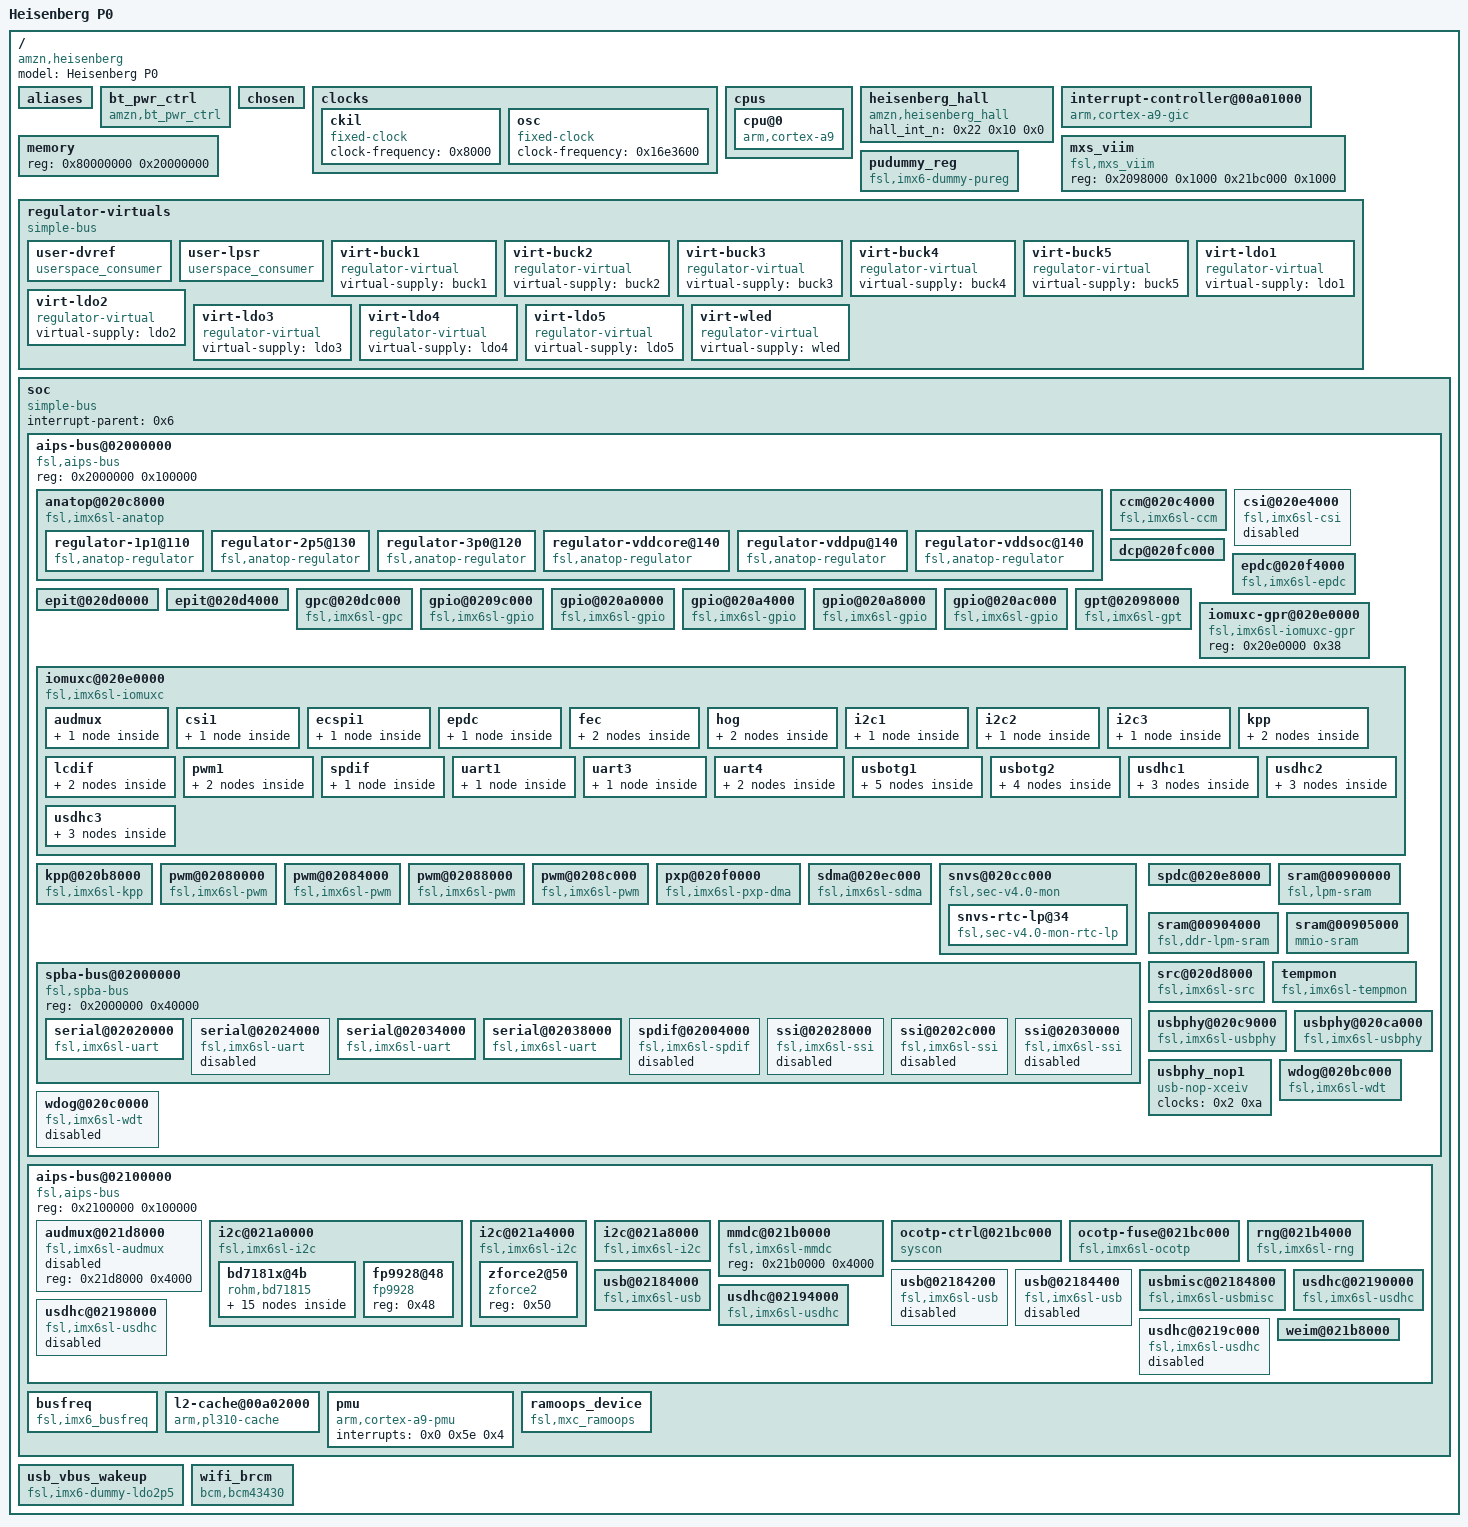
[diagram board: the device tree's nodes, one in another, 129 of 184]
/dts-v1/;

/ {
	#address-cells = <0x1>;
	#size-cells = <0x1>;
	compatible = "amzn,heisenberg", "fsl,imx6sl";
	model = "Heisenberg P0";

	aliases {
		csi0 = "/soc/aips-bus@02000000/csi@020e4000";
		gpio0 = "/soc/aips-bus@02000000/gpio@0209c000";
		gpio1 = "/soc/aips-bus@02000000/gpio@020a0000";
		gpio2 = "/soc/aips-bus@02000000/gpio@020a4000";
		gpio3 = "/soc/aips-bus@02000000/gpio@020a8000";
		gpio4 = "/soc/aips-bus@02000000/gpio@020ac000";
		mmc0 = "/soc/aips-bus@02100000/usdhc@02194000";
		mmc1 = "/soc/aips-bus@02100000/usdhc@02190000";
		mmc2 = "/soc/aips-bus@02100000/usdhc@02198000";
		mmc3 = "/soc/aips-bus@02100000/usdhc@0219c000";
		serial0 = "/soc/aips-bus@02000000/spba-bus@02000000/serial@02020000";
		serial1 = "/soc/aips-bus@02000000/spba-bus@02000000/serial@02024000";
		serial2 = "/soc/aips-bus@02000000/spba-bus@02000000/serial@02034000";
		serial3 = "/soc/aips-bus@02000000/spba-bus@02000000/serial@02038000";
		usbphy0 = "/soc/aips-bus@02000000/usbphy@020c9000";
		usbphy1 = "/soc/aips-bus@02000000/usbphy@020ca000";
	};

	bt_pwr_ctrl {
		bt_dev_wake = <0x27 0xa 0x0>;
		bt_host_wake = <0x26 0x1d 0x0>;
		bt_rst = <0x25 0x13 0x0>;
		compatible = "amzn,bt_pwr_ctrl";
	};

	chosen {
	};

	clocks {
		#address-cells = <0x1>;
		#size-cells = <0x0>;

		ckil {
			clock-frequency = <0x8000>;
			compatible = "fixed-clock";
		};

		osc {
			clock-frequency = <0x16e3600>;
			compatible = "fixed-clock";
		};
	};

	cpus {
		#address-cells = <0x1>;
		#size-cells = <0x0>;

		cpu@0 {
			arm-supply = <0x3>;
			clock-latency = <0xee6c>;
			clock-names = "arm", "pll2_pfd2_396m", "step", "pll1_sw", "pll1_sys";
			clocks = <0x2 0x5f 0x2 0x14 0x2 0x1d 0x2 0x1e 0x2 0x3>;
			compatible = "arm,cortex-a9";
			device_type = "cpu";
			fsl,soc-operating-points = <0xf32a0 0x12b128 0x60ae0 0x11edd8>;
			next-level-cache = <0x1>;
			operating-points = <0xf32a0 0x137478 0x60ae0 0xee098>;
			pu-supply = <0x4>;
			reg = <0x0>;
			soc-supply = <0x5>;
		};
	};

	heisenberg_hall {
		compatible = "amzn,heisenberg_hall";
		hall_int_n = <0x22 0x10 0x0>;
		status = "okay";
	};

	interrupt-controller@00a01000 {
		#address-cells = <0x1>;
		#interrupt-cells = <0x3>;
		#size-cells = <0x1>;
		compatible = "arm,cortex-a9-gic";
		interrupt-controller;
		linux,phandle = <0x6>;
		phandle = <0x6>;
		reg = <0xa01000 0x1000 0xa00100 0x100>;
	};

	memory {
		device_type = "memory";
		reg = <0x80000000 0x20000000>;
	};

	mxs_viim {
		compatible = "fsl,mxs_viim";
		reg = <0x2098000 0x1000 0x21bc000 0x1000>;
	};

	pudummy_reg {
		compatible = "fsl,imx6-dummy-pureg";
		linux,phandle = <0x4>;
		phandle = <0x4>;
	};

	regulator-virtuals {
		compatible = "simple-bus";

		user-dvref {
			compatible = "userspace_consumer";
			suck-supply = "dvref";
			uc-name = "dvref";
		};

		user-lpsr {
			compatible = "userspace_consumer";
			suck-supply = "lpsr";
			uc-name = "lpsr";
		};

		virt-buck1 {
			compatible = "regulator-virtual";
			virtual-supply = "buck1";
		};

		virt-buck2 {
			compatible = "regulator-virtual";
			virtual-supply = "buck2";
		};

		virt-buck3 {
			compatible = "regulator-virtual";
			virtual-supply = "buck3";
		};

		virt-buck4 {
			compatible = "regulator-virtual";
			virtual-supply = "buck4";
		};

		virt-buck5 {
			compatible = "regulator-virtual";
			virtual-supply = "buck5";
		};

		virt-ldo1 {
			compatible = "regulator-virtual";
			virtual-supply = "ldo1";
		};

		virt-ldo2 {
			compatible = "regulator-virtual";
			virtual-supply = "ldo2";
		};

		virt-ldo3 {
			compatible = "regulator-virtual";
			virtual-supply = "ldo3";
		};

		virt-ldo4 {
			compatible = "regulator-virtual";
			virtual-supply = "ldo4";
		};

		virt-ldo5 {
			compatible = "regulator-virtual";
			virtual-supply = "ldo5";
		};

		virt-wled {
			compatible = "regulator-virtual";
			virtual-supply = "wled";
		};
	};

	soc {
		#address-cells = <0x1>;
		#size-cells = <0x1>;
		compatible = "simple-bus";
		interrupt-parent = <0x6>;
		ranges;

		aips-bus@02000000 {
			#address-cells = <0x1>;
			#size-cells = <0x1>;
			compatible = "fsl,aips-bus", "simple-bus";
			ranges;
			reg = <0x2000000 0x100000>;

			anatop@020c8000 {
				compatible = "fsl,imx6sl-anatop", "fsl,imx6q-anatop", "syscon", "simple-bus";
				interrupts = <0x0 0x31 0x4 0x0 0x36 0x4 0x0 0x7f 0x4>;
				linux,phandle = <0xc>;
				phandle = <0xc>;
				reg = <0x20c8000 0x1000>;

				regulator-1p1@110 {
					anatop-enable-bit = <0x0>;
					anatop-max-voltage = <0x14fb18>;
					anatop-min-bit-val = <0x4>;
					anatop-min-voltage = <0xc3500>;
					anatop-reg-offset = <0x110>;
					anatop-vol-bit-shift = <0x8>;
					anatop-vol-bit-width = <0x5>;
					compatible = "fsl,anatop-regulator";
					regulator-always-on;
					regulator-max-microvolt = <0x14fb18>;
					regulator-min-microvolt = <0xc3500>;
					regulator-name = "vdd1p1";
				};

				regulator-2p5@130 {
					anatop-enable-bit = <0x0>;
					anatop-max-voltage = <0x2b7cd0>;
					anatop-min-bit-val = <0x0>;
					anatop-min-voltage = <0x200b20>;
					anatop-reg-offset = <0x130>;
					anatop-vol-bit-shift = <0x8>;
					anatop-vol-bit-width = <0x5>;
					compatible = "fsl,anatop-regulator";
					regulator-always-on;
					regulator-max-microvolt = <0x2b7cd0>;
					regulator-min-microvolt = <0x200b20>;
					regulator-name = "vdd2p5";
				};

				regulator-3p0@120 {
					anatop-enable-bit = <0x0>;
					anatop-max-voltage = <0x33e140>;
					anatop-min-bit-val = <0x0>;
					anatop-min-voltage = <0x280de8>;
					anatop-reg-offset = <0x120>;
					anatop-vol-bit-shift = <0x8>;
					anatop-vol-bit-width = <0x5>;
					compatible = "fsl,anatop-regulator";
					linux,phandle = <0xe>;
					phandle = <0xe>;
					regulator-max-microvolt = <0x33e140>;
					regulator-min-microvolt = <0x280de8>;
					regulator-name = "vdd3p0";
				};

				regulator-vddcore@140 {
					anatop-delay-bit-shift = <0x18>;
					anatop-delay-bit-width = <0x2>;
					anatop-delay-reg-offset = <0x170>;
					anatop-max-voltage = <0x162010>;
					anatop-min-bit-val = <0x1>;
					anatop-min-voltage = <0xb1008>;
					anatop-reg-offset = <0x140>;
					anatop-vol-bit-shift = <0x0>;
					anatop-vol-bit-width = <0x5>;
					compatible = "fsl,anatop-regulator";
					regulator-max-microvolt = <0x162010>;
					regulator-min-microvolt = <0xb1008>;
					regulator-name = "cpu";
				};

				regulator-vddpu@140 {
					anatop-delay-bit-shift = <0x1a>;
					anatop-delay-bit-width = <0x2>;
					anatop-delay-reg-offset = <0x170>;
					anatop-max-voltage = <0x162010>;
					anatop-min-bit-val = <0x1>;
					anatop-min-voltage = <0xb1008>;
					anatop-reg-offset = <0x140>;
					anatop-vol-bit-shift = <0x9>;
					anatop-vol-bit-width = <0x5>;
					compatible = "fsl,anatop-regulator";
					linux,phandle = <0xf>;
					phandle = <0xf>;
					regulator-max-microvolt = <0x162010>;
					regulator-min-microvolt = <0xb1008>;
					regulator-name = "vddpu";
				};

				regulator-vddsoc@140 {
					anatop-delay-bit-shift = <0x1c>;
					anatop-delay-bit-width = <0x2>;
					anatop-delay-reg-offset = <0x170>;
					anatop-max-voltage = <0x162010>;
					anatop-min-bit-val = <0x1>;
					anatop-min-voltage = <0xb1008>;
					anatop-reg-offset = <0x140>;
					anatop-vol-bit-shift = <0x12>;
					anatop-vol-bit-width = <0x5>;
					compatible = "fsl,anatop-regulator";
					regulator-max-microvolt = <0x162010>;
					regulator-min-microvolt = <0xb1008>;
					regulator-name = "vddsoc";
				};
			};

			ccm@020c4000 {
				#clock-cells = <0x1>;
				compatible = "fsl,imx6sl-ccm";
				interrupts = <0x0 0x57 0x4 0x0 0x58 0x4>;
				linux,phandle = <0x2>;
				phandle = <0x2>;
				reg = <0x20c4000 0x4000>;
			};

			csi@020e4000 {
				clock-names = "disp-axi", "csi_mclk", "dcic";
				clocks = <0x2 0x0 0x2 0x0 0x2 0x0>;
				compatible = "fsl,imx6sl-csi";
				interrupts = <0x0 0x7 0x4>;
				reg = <0x20e4000 0x4000>;
				status = "disabled";
			};

			dcp@020fc000 {
				interrupts = <0x0 0x63 0x4>;
				reg = <0x20fc000 0x4000>;
			};

			epdc@020f4000 {
				clock-names = "epdc_axi", "epdc_pix";
				clocks = <0x2 0x70 0x2 0x73>;
				compatible = "fsl,imx6sl-epdc", "fsl,imx6dl-epdc";
				interrupts = <0x0 0x61 0x4>;
				pinctrl-0 = <0x13>;
				pinctrl-names = "default";
				reg = <0x20f4000 0x4000>;
				status = "okay";
			};

			epit@020d0000 {
				interrupts = <0x0 0x38 0x4>;
				reg = <0x20d0000 0x4000>;
			};

			epit@020d4000 {
				interrupts = <0x0 0x39 0x4>;
				reg = <0x20d4000 0x4000>;
			};

			gpc@020dc000 {
				clock-names = "gpu2d_podf", "gpu2d_ovg", "ipg", "lcd_axi", "lcd_pix", "epdc_axi", "epdc_pix", "pxp_axi";
				clocks = <0x2 0x50 0x2 0x69 0x2 0x3f 0x2 0x71 0x2 0x72 0x2 0x70 0x2 0x73 0x2 0x6f>;
				compatible = "fsl,imx6sl-gpc", "fsl,imx6q-gpc";
				interrupts = <0x0 0x59 0x4>;
				pu-supply = <0xf>;
				reg = <0x20dc000 0x4000>;
			};

			gpio@0209c000 {
				#gpio-cells = <0x2>;
				#interrupt-cells = <0x2>;
				compatible = "fsl,imx6sl-gpio", "fsl,imx35-gpio";
				gpio-controller;
				interrupt-controller;
				interrupts = <0x0 0x42 0x4 0x0 0x43 0x4>;
				reg = <0x209c000 0x4000>;
			};

			gpio@020a0000 {
				#gpio-cells = <0x2>;
				#interrupt-cells = <0x2>;
				compatible = "fsl,imx6sl-gpio", "fsl,imx35-gpio";
				gpio-controller;
				interrupt-controller;
				interrupts = <0x0 0x44 0x4 0x0 0x45 0x4>;
				linux,phandle = <0x25>;
				phandle = <0x25>;
				reg = <0x20a0000 0x4000>;
			};

			gpio@020a4000 {
				#gpio-cells = <0x2>;
				#interrupt-cells = <0x2>;
				compatible = "fsl,imx6sl-gpio", "fsl,imx35-gpio";
				gpio-controller;
				interrupt-controller;
				interrupts = <0x0 0x46 0x4 0x0 0x47 0x4>;
				linux,phandle = <0x26>;
				phandle = <0x26>;
				reg = <0x20a4000 0x4000>;
			};

			gpio@020a8000 {
				#gpio-cells = <0x2>;
				#interrupt-cells = <0x2>;
				compatible = "fsl,imx6sl-gpio", "fsl,imx35-gpio";
				gpio-controller;
				interrupt-controller;
				interrupts = <0x0 0x48 0x4 0x0 0x49 0x4>;
				linux,phandle = <0x22>;
				phandle = <0x22>;
				reg = <0x20a8000 0x4000>;
			};

			gpio@020ac000 {
				#gpio-cells = <0x2>;
				#interrupt-cells = <0x2>;
				compatible = "fsl,imx6sl-gpio", "fsl,imx35-gpio";
				gpio-controller;
				interrupt-controller;
				interrupts = <0x0 0x4a 0x4 0x0 0x4b 0x4>;
				linux,phandle = <0x27>;
				phandle = <0x27>;
				reg = <0x20ac000 0x4000>;
			};

			gpt@02098000 {
				clock-names = "ipg", "per";
				clocks = <0x2 0x67 0x2 0x68>;
				compatible = "fsl,imx6sl-gpt";
				interrupts = <0x0 0x37 0x4>;
				reg = <0x2098000 0x4000>;
			};

			iomuxc-gpr@020e0000 {
				compatible = "fsl,imx6sl-iomuxc-gpr", "syscon";
				reg = <0x20e0000 0x38>;
			};

			iomuxc@020e0000 {
				compatible = "fsl,imx6sl-iomuxc";
				pinctrl-0 = <0x10>;
				pinctrl-1 = <0x11>;
				pinctrl-names = "default", "sleep";
				reg = <0x20e0000 0x4000>;

				audmux {

					audmux-1 {
						fsl,pins = <0x54 0x2ac 0x0 0x0 0x0 0x4130b0 0x5c 0x2b4 0x0 0x0 0x0 0x4130b0 0x60 0x2b8 0x0 0x0 0x0 0x4110b0 0x64 0x2bc 0x0 0x0 0x0 0x4130b0 0x4c 0x2a4 0x0 0x0 0x0 0x4130b0>;
					};
				};

				csi1 {

					csigrp-0 {
						fsl,pins = <0xd8 0x3c8 0x0 0x3 0x0 0x110b0 0xd0 0x3c0 0x674 0x3 0x1 0x110b0 0xdc 0x3cc 0x678 0x3 0x1 0x110b0 0xd4 0x3c4 0x670 0x3 0x1 0x110b0 0x114 0x404 0x654 0x3 0x0 0x110b0 0x110 0x400 0x650 0x3 0x0 0x110b0 0xc4 0x3b4 0x64c 0x3 0x0 0x110b0 0xc0 0x3b0 0x648 0x3 0x0 0x110b0 0xbc 0x3ac 0x644 0x3 0x0 0x110b0 0xb8 0x3a8 0x640 0x3 0x0 0x110b0 0xb4 0x3a4 0x63c 0x3 0x0 0x110b0 0xb0 0x3a0 0x638 0x3 0x0 0x110b0 0x94 0x384 0x634 0x3 0x0 0x110b0 0x90 0x380 0x630 0x3 0x0 0x110b0 0x11c 0x40c 0x0 0x5 0x0 0x80000000 0x118 0x408 0x0 0x5 0x0 0x80000000>;
					};
				};

				ecspi1 {

					ecspi1grp-1 {
						fsl,pins = <0x68 0x358 0x684 0x0 0x0 0x100b1 0x6c 0x35c 0x688 0x0 0x0 0x100b1 0x70 0x360 0x67c 0x0 0x0 0x100b1>;
					};
				};

				epdc {

					epdcgrp-0 {
						fsl,pins = <0x90 0x380 0x0 0x0 0x0 0x4110a1 0x94 0x384 0x0 0x0 0x0 0x4110a1 0xb0 0x3a0 0x0 0x0 0x0 0x4110a1 0xb4 0x3a4 0x0 0x0 0x0 0x4110a1 0xb8 0x3a8 0x0 0x0 0x0 0x4110a1 0xbc 0x3ac 0x0 0x0 0x0 0x4110a1 0xc0 0x3b0 0x0 0x0 0x0 0x4110a1 0xc4 0x3b4 0x0 0x0 0x0 0x4110a1 0xd0 0x3c0 0x0 0x0 0x0 0x4110a0 0xdc 0x3cc 0x0 0x0 0x0 0x4110a0 0xd4 0x3c4 0x0 0x0 0x0 0x4110a0 0x110 0x400 0x0 0x0 0x0 0x4110a9 0x118 0x408 0x0 0x0 0x0 0x4110a9 0x114 0x404 0x0 0x0 0x0 0x4110a1 0x100 0x3f0 0x0 0x0 0x0 0x4110a0>;
						linux,phandle = <0x13>;
						phandle = <0x13>;
					};
				};

				fec {

					fecgrp-1 {
						fsl,pins = <0x12c 0x41c 0x0 0x0 0x0 0x1b0b0 0x130 0x420 0x6f4 0x0 0x1 0x1b0b0 0x128 0x418 0x704 0x0 0x1 0x1b0b0 0x13c 0x42c 0x6f8 0x0 0x0 0x1b0b0 0x140 0x430 0x6fc 0x0 0x1 0x1b0b0 0x148 0x438 0x0 0x0 0x0 0x1b0b0 0x14c 0x43c 0x0 0x0 0x0 0x1b0b0 0x150 0x440 0x0 0x0 0x0 0x1b0b0 0x134 0x424 0x0 0x0 0x0 0x4001b0a8>;
					};

					fecgrp-1-sleep {
						fsl,pins = <0x12c 0x41c 0x0 0x5 0x0 0x3080 0x128 0x418 0x0 0x5 0x0 0x3080 0x13c 0x42c 0x0 0x5 0x0 0x3080 0x140 0x430 0x0 0x5 0x0 0x3080 0x148 0x438 0x0 0x5 0x0 0x3080 0x14c 0x43c 0x0 0x5 0x0 0x3080 0x150 0x440 0x0 0x5 0x0 0x3080 0x134 0x424 0x0 0x5 0x0 0x3080>;
					};
				};

				hog {

					hoggrp {
						fsl,pins = <0x2a0 0x5a8 0x0 0x0 0x0 0x4128b0 0x150 0x440 0x0 0x5 0x0 0x4100b0 0x24c 0x554 0x0 0x5 0x0 0x4100b0 0x250 0x558 0x0 0x5 0x0 0x4100b0 0x194 0x49c 0x0 0x5 0x0 0x4130b0 0x198 0x4a0 0x0 0x5 0x0 0x4130b0 0x1ac 0x4b4 0x0 0x5 0x0 0x4170b0 0x218 0x520 0x0 0x5 0x0 0x4000b0 0x1f4 0x4fc 0x5e4 0x4 0x1 0x4100b0 0x1f8 0x500 0x5f4 0x4 0x1 0x4100b0 0x1fc 0x504 0x5f8 0x4 0x1 0x4100b0 0x200 0x508 0x5e8 0x4 0x1 0x4100b0 0x19c 0x4a4 0x0 0x5 0x0 0x100b0 0x18c 0x494 0x0 0x5 0x0 0x100b0 0x190 0x498 0x0 0x5 0x0 0x100b0 0x17c 0x484 0x0 0x5 0x0 0x4100b0 0x130 0x420 0x0 0x5 0x0 0x4100b0 0x13c 0x42c 0x0 0x5 0x0 0x4100b0 0xe0 0x3d0 0x0 0x5 0x0 0x4130b0 0xc8 0x3b8 0x0 0x5 0x0 0x4130b0 0xcc 0x3bc 0x0 0x5 0x0 0x4130b0 0x98 0x388 0x0 0x5 0x0 0x4130b0 0x9c 0x38c 0x0 0x5 0x0 0x4130b0 0xa0 0x390 0x0 0x5 0x0 0x4130b0 0xa4 0x394 0x0 0x5 0x0 0x4130b0 0xa8 0x398 0x0 0x5 0x0 0x4130b0 0xac 0x39c 0x0 0x5 0x0 0x4130b0 0x11c 0x40c 0x0 0x5 0x0 0x4130b0 0x104 0x3f4 0x0 0x5 0x0 0x4130b0 0xd8 0x3c8 0x0 0x5 0x0 0x4130b0 0xe4 0x3d4 0x0 0x5 0x0 0x4130b0 0xe8 0x3d8 0x0 0x5 0x0 0x4130b0 0xec 0x3dc 0x0 0x5 0x0 0x4130b0 0xf0 0x3e0 0x0 0x5 0x0 0x4130b0 0xe0 0x3d0 0x0 0x5 0x0 0x4130b0 0xf4 0x3e4 0x0 0x5 0x0 0x4130b0 0xf8 0x3e8 0x0 0x5 0x0 0x4130b0 0xfc 0x3ec 0x0 0x5 0x0 0x4130b0 0x210 0x518 0x0 0x5 0x0 0x4130b0 0x214 0x51c 0x0 0x5 0x0 0x4130b0 0x21c 0x524 0x0 0x5 0x0 0x4130b0 0x1b0 0x4b8 0x0 0x5 0x0 0x4130b0 0x1b4 0x4bc 0x0 0x5 0x0 0x4130b0 0x1e0 0x4e8 0x0 0x5 0x0 0x4130b0 0x204 0x50c 0x0 0x5 0x0 0x4130b0 0x208 0x510 0x0 0x5 0x0 0x4130b0 0x20c 0x514 0x0 0x5 0x0 0x4130b0 0x1b8 0x4c0 0x0 0x5 0x0 0x4130b0 0x1bc 0x4c4 0x0 0x5 0x0 0x4130b0 0x1c0 0x4c8 0x0 0x5 0x0 0x4130b0 0x1c4 0x4cc 0x0 0x5 0x0 0x4130b0 0x1c8 0x4d0 0x0 0x5 0x0 0x4130b0 0x1cc 0x4d4 0x0 0x5 0x0 0x4130b0 0x1d0 0x4d8 0x0 0x5 0x0 0x4130b0 0x1d4 0x4dc 0x0 0x5 0x0 0x4130b0 0x1d8 0x4e0 0x0 0x5 0x0 0x4130b0 0x1dc 0x4e4 0x0 0x5 0x0 0x4130b0 0x1e4 0x4ec 0x0 0x5 0x0 0x4130b0 0x1e8 0x4f0 0x0 0x5 0x0 0x4130b0 0x1ec 0x4f4 0x0 0x5 0x0 0x4130b0 0x1f0 0x4f8 0x0 0x5 0x0 0x4130b0 0x58 0x2b0 0x0 0x5 0x0 0x4130b0 0x50 0x2a8 0x0 0x5 0x0 0x4130b0 0x54 0x2ac 0x0 0x5 0x0 0x4130b0 0x64 0x2bc 0x0 0x5 0x0 0x4130b0 0x60 0x2b8 0x0 0x5 0x0 0x4130b0 0x4c 0x2a4 0x0 0x5 0x0 0x4130b0 0x80 0x370 0x0 0x5 0x0 0x4130b0 0x7c 0x36c 0x0 0x5 0x0 0x4130b0 0x78 0x368 0x0 0x5 0x0 0x4130b0 0x84 0x374 0x0 0x5 0x0 0x4130b0 0x144 0x434 0x0 0x5 0x0 0x4130b0 0x138 0x428 0x0 0x5 0x0 0x4130b0 0x128 0x418 0x0 0x5 0x0 0x4130b0 0x140 0x430 0x0 0x5 0x0 0x4130b0 0x14c 0x43c 0x0 0x5 0x0 0x4130b0 0x12c 0x41c 0x0 0x5 0x0 0x4130b0 0x148 0x438 0x0 0x5 0x0 0x4130b0 0x134 0x424 0x0 0x5 0x0 0x4130b0 0x280 0x588 0x0 0x5 0x0 0x4130b0 0x284 0x58c 0x0 0x5 0x0 0x4130b0 0x288 0x590 0x0 0x5 0x0 0x4130b0 0x28c 0x594 0x0 0x5 0x0 0x4130b0 0x290 0x598 0x0 0x5 0x0 0x4130b0 0x294 0x59c 0x0 0x5 0x0 0x4130b0 0x1a8 0x4b0 0x0 0x5 0x0 0x4130b0 0x170 0x478 0x0 0x5 0x0 0x4130b0 0x174 0x47c 0x0 0x5 0x0 0x4130b0 0x178 0x480 0x0 0x5 0x0 0x4130b0 0x180 0x488 0x0 0x5 0x0 0x4130b0 0x184 0x48c 0x0 0x5 0x0 0x4130b0 0x188 0x490 0x0 0x5 0x0 0x4130b0 0x220 0x528 0x0 0x5 0x0 0x4130b0 0x154 0x444 0x0 0x5 0x0 0x4130b0 0x158 0x448 0x0 0x5 0x0 0x4130b0 0x224 0x52c 0x0 0x5 0x0 0x4130b0 0x228 0x530 0x0 0x5 0x0 0x4130b0 0x244 0x54c 0x814 0x4 0x4 0x1b0b1 0x248 0x550 0x0 0x4 0x0 0x1b0b1>;
						linux,phandle = <0x10>;
						phandle = <0x10>;
					};

					hoggrp_sleep {
						fsl,pins = <0x2a0 0x5a8 0x0 0x0 0x0 0x4128b0 0x130 0x420 0x0 0x5 0x0 0x4100b0 0x150 0x440 0x0 0x5 0x0 0x4100b0 0x248 0x550 0x0 0x5 0x0 0x4130b0 0x244 0x54c 0x0 0x5 0x0 0x4130b0>;
						linux,phandle = <0x11>;
						phandle = <0x11>;
					};
				};

				i2c1 {

					i2c1grp-1 {
						fsl,pins = <0x15c 0x44c 0x71c 0x0 0x2 0x404108b1 0x160 0x450 0x720 0x0 0x2 0x404108b1>;
						linux,phandle = <0x21>;
						phandle = <0x21>;
					};
				};

				i2c2 {

					i2c2grp-1 {
						fsl,pins = <0x164 0x454 0x724 0x0 0x1 0x400108a8 0x168 0x458 0x728 0x0 0x1 0x400108a8>;
						linux,phandle = <0x23>;
						phandle = <0x23>;
					};
				};

				i2c3 {

					i2c3grp-1 {
						fsl,pins = <0x108 0x3f8 0x72c 0x1 0x1 0x400108a8 0x10c 0x3fc 0x730 0x1 0x1 0x400108a8>;
						linux,phandle = <0x24>;
						phandle = <0x24>;
					};
				};

				kpp {

					kpp_grp_1 {
						fsl,pins = <0x1a0 0x4a8 0x0 0x5 0x0 0x100b0 0x1a4 0x4ac 0x0 0x5 0x0 0x108b0 0x16c 0x474 0x0 0x5 0x0 0x100b0>;
						linux,phandle = <0xb>;
						phandle = <0xb>;
					};

					kpp_grp_1_sleep {
						fsl,pins = <0x18c 0x494 0x0 0x5 0x0 0x3080 0x190 0x498 0x0 0x5 0x0 0x3080 0x194 0x49c 0x0 0x5 0x0 0x3080 0x16c 0x474 0x0 0x5 0x0 0x3080 0x170 0x478 0x0 0x5 0x0 0x3080 0x174 0x47c 0x0 0x5 0x0 0x3080>;
					};
				};

				lcdif {

					lcdifctrlgrp-0 {
						fsl,pins = <0x1ac 0x4b4 0x0 0x0 0x0 0x1b0b0 0x210 0x518 0x0 0x0 0x0 0x1b0b0 0x214 0x51c 0x774 0x0 0x0 0x1b0b0 0x21c 0x524 0x0 0x0 0x0 0x1b0b0>;
					};

					lcdifdatgrp-0 {
						fsl,pins = <0x1b0 0x4b8 0x778 0x0 0x1 0x1b0b0 0x1b4 0x4bc 0x77c 0x0 0x1 0x1b0b0 0x1e0 0x4e8 0x780 0x0 0x1 0x1b0b0 0x1f4 0x4fc 0x784 0x0 0x1 0x1b0b0 0x1f8 0x500 0x788 0x0 0x1 0x1b0b0 0x1fc 0x504 0x78c 0x0 0x1 0x1b0b0 0x200 0x508 0x790 0x0 0x1 0x1b0b0 0x204 0x50c 0x794 0x0 0x1 0x1b0b0 0x208 0x510 0x798 0x0 0x1 0x1b0b0 0x20c 0x514 0x79c 0x0 0x1 0x1b0b0 0x1b8 0x4c0 0x7a0 0x0 0x1 0x1b0b0 0x1bc 0x4c4 0x7a4 0x0 0x1 0x1b0b0 0x1c0 0x4c8 0x7a8 0x0 0x1 0x1b0b0 0x1c4 0x4cc 0x7ac 0x0 0x1 0x1b0b0 0x1c8 0x4d0 0x7b0 0x0 0x1 0x1b0b0 0x1cc 0x4d4 0x7b4 0x0 0x1 0x1b0b0 0x1d0 0x4d8 0x7b8 0x0 0x1 0x1b0b0 0x1d4 0x4dc 0x7bc 0x0 0x1 0x1b0b0 0x1d8 0x4e0 0x7c0 0x0 0x1 0x1b0b0 0x1dc 0x4e4 0x7c4 0x0 0x1 0x1b0b0 0x1e4 0x4ec 0x7c8 0x0 0x1 0x1b0b0 0x1e8 0x4f0 0x7cc 0x0 0x1 0x1b0b0 0x1ec 0x4f4 0x7d0 0x0 0x1 0x1b0b0 0x1f0 0x4f8 0x7d4 0x0 0x1 0x1b0b0>;
					};
				};

				pwm1 {

					pwm1grp-0 {
						fsl,pins = <0x220 0x528 0x0 0x0 0x0 0x110b0>;
					};

					pwm1grp-0-sleep {
						fsl,pins = <0x220 0x528 0x0 0x5 0x0 0x3080>;
					};
				};

				spdif {

					spdifgrp-1 {
						fsl,pins = <0x26c 0x574 0x0 0x4 0x0 0x80000000>;
					};
				};

				uart1 {

					uart1grp-1 {
						fsl,pins = <0x298 0x5a0 0x7fc 0x0 0x0 0x41b0b1 0x29c 0x5a4 0x0 0x0 0x0 0x41b0b1>;
						linux,phandle = <0x8>;
						phandle = <0x8>;
					};
				};

				uart3 {

					uart3grp-1 {
						fsl,pins = <0x8c 0x37c 0x0 0x2 0x0 0x41b0b1 0x88 0x378 0x808 0x2 0x2 0x41b0b1 0x120 0x410 0x80c 0x2 0x4 0x41b0b1 0x124 0x414 0x0 0x2 0x0 0x4130b1>;
						linux,phandle = <0x9>;
						phandle = <0x9>;
					};
				};

				uart4 {

					uart4dtegrp-1 {
						fsl,pins = <0x248 0x550 0x814 0x4 0x5 0x1b0b1 0x244 0x54c 0x0 0x4 0x0 0x1b0b1 0x24c 0x554 0x0 0x4 0x0 0x1b0b1 0x250 0x558 0x810 0x4 0x5 0x1b0b1>;
					};

					uart4grp-1 {
						fsl,pins = <0x244 0x54c 0x814 0x4 0x4 0x1b0b1 0x248 0x550 0x0 0x4 0x0 0x1b0b1>;
						linux,phandle = <0xa>;
						phandle = <0xa>;
					};
				};

				usbotg1 {

					usbotg1grp-1 {
						fsl,pins = <0xe0 0x3d0 0x5dc 0x4 0x0 0x17059>;
						linux,phandle = <0x17>;
						phandle = <0x17>;
					};

					usbotg1grp-2 {
						fsl,pins = <0x13c 0x42c 0x5dc 0x2 0x1 0x17059>;
					};

					usbotg1grp-3 {
						fsl,pins = <0x1b4 0x4bc 0x5dc 0x2 0x2 0x17059>;
					};

					usbotg1grp-4 {
						fsl,pins = <0x228 0x530 0x5dc 0x3 0x3 0x17059>;
					};

					usbotg1grp-5 {
						fsl,pins = <0x288 0x590 0x5dc 0x4 0x4 0x17059>;
					};
				};

				usbotg2 {

					usbotg2grp-1 {
						fsl,pins = <0x70 0x360 0x820 0x6 0x0 0x17059>;
					};

					usbotg2grp-2 {
						fsl,pins = <0x80 0x370 0x820 0x6 0x1 0x17059>;
					};

					usbotg2grp-3 {
						fsl,pins = <0x1a0 0x4a8 0x820 0x6 0x2 0x17059>;
					};

					usbotg2grp-4 {
						fsl,pins = <0x290 0x598 0x820 0x6 0x3 0x17059>;
					};
				};

				usdhc1 {

					usdhc1grp-1 {
						fsl,pins = <0x230 0x538 0x0 0x0 0x0 0x407059 0x22c 0x534 0x0 0x0 0x0 0x4000d9 0x234 0x53c 0x0 0x0 0x0 0x407059 0x238 0x540 0x0 0x0 0x0 0x407059 0x23c 0x544 0x0 0x0 0x0 0x407059 0x240 0x548 0x0 0x0 0x0 0x407059>;
						linux,phandle = <0x1b>;
						phandle = <0x1b>;
					};

					usdhc1grp-1-100mhz {
						fsl,pins = <0x230 0x538 0x0 0x0 0x0 0x4070a9 0x22c 0x534 0x0 0x0 0x0 0x4000f9 0x234 0x53c 0x0 0x0 0x0 0x4070a9 0x238 0x540 0x0 0x0 0x0 0x4070a9 0x23c 0x544 0x0 0x0 0x0 0x4070a9 0x240 0x548 0x0 0x0 0x0 0x4070a9>;
						linux,phandle = <0x1c>;
						phandle = <0x1c>;
					};

					usdhc1grp-1-200mhz {
						fsl,pins = <0x230 0x538 0x0 0x0 0x0 0x4070e9 0x22c 0x534 0x0 0x0 0x0 0x4000f9 0x234 0x53c 0x0 0x0 0x0 0x4070e9 0x238 0x540 0x0 0x0 0x0 0x4070e9 0x23c 0x544 0x0 0x0 0x0 0x4070e9 0x240 0x548 0x0 0x0 0x0 0x4070e9>;
						linux,phandle = <0x1d>;
						phandle = <0x1d>;
					};
				};

				usdhc2 {

					usdhc2grp-1 {
						fsl,pins = <0x258 0x560 0x0 0x0 0x0 0x407059 0x254 0x55c 0x0 0x0 0x0 0x400059 0x25c 0x564 0x0 0x0 0x0 0x407059 0x260 0x568 0x0 0x0 0x0 0x407059 0x264 0x56c 0x0 0x0 0x0 0x407059 0x268 0x570 0x0 0x0 0x0 0x407059 0x26c 0x574 0x0 0x0 0x0 0x407059 0x270 0x578 0x0 0x0 0x0 0x407059 0x274 0x57c 0x0 0x0 0x0 0x407059 0x278 0x580 0x0 0x0 0x0 0x407059 0x27c 0x584 0x0 0x0 0x0 0x407059>;
						linux,phandle = <0x1e>;
						phandle = <0x1e>;
					};

					usdhc2grp-1-100mhz {
						fsl,pins = <0x258 0x560 0x0 0x0 0x0 0x4070b9 0x254 0x55c 0x0 0x0 0x0 0x4000b9 0x25c 0x564 0x0 0x0 0x0 0x4070b9 0x260 0x568 0x0 0x0 0x0 0x4070b9 0x264 0x56c 0x0 0x0 0x0 0x4070b9 0x268 0x570 0x0 0x0 0x0 0x4070b9 0x26c 0x574 0x0 0x0 0x0 0x4070b9 0x270 0x578 0x0 0x0 0x0 0x4070b9 0x274 0x57c 0x0 0x0 0x0 0x4070b9 0x278 0x580 0x0 0x0 0x0 0x4070b9 0x27c 0x584 0x0 0x0 0x0 0x4070b9>;
						linux,phandle = <0x1f>;
						phandle = <0x1f>;
					};

					usdhc2grp-1-200mhz {
						fsl,pins = <0x258 0x560 0x0 0x0 0x0 0x4070f9 0x254 0x55c 0x0 0x0 0x0 0x4000f9 0x25c 0x564 0x0 0x0 0x0 0x4070f9 0x260 0x568 0x0 0x0 0x0 0x4070f9 0x264 0x56c 0x0 0x0 0x0 0x4070f9 0x268 0x570 0x0 0x0 0x0 0x4070f9 0x26c 0x574 0x0 0x0 0x0 0x4070f9 0x270 0x578 0x0 0x0 0x0 0x4070f9 0x274 0x57c 0x0 0x0 0x0 0x4070f9 0x278 0x580 0x0 0x0 0x0 0x4070f9 0x27c 0x584 0x0 0x0 0x0 0x4070f9>;
						linux,phandle = <0x20>;
						phandle = <0x20>;
					};
				};

				usdhc3 {

					usdhc3grp-1 {
						fsl,pins = <0x284 0x58c 0x0 0x0 0x0 0x17059 0x280 0x588 0x0 0x0 0x0 0x10059 0x288 0x590 0x0 0x0 0x0 0x17059 0x28c 0x594 0x0 0x0 0x0 0x17059 0x290 0x598 0x0 0x0 0x0 0x17059 0x294 0x59c 0x0 0x0 0x0 0x17059>;
					};

					usdhc3grp-1-100mhz {
						fsl,pins = <0x284 0x58c 0x0 0x0 0x0 0x170b9 0x280 0x588 0x0 0x0 0x0 0x100b9 0x288 0x590 0x0 0x0 0x0 0x170b9 0x28c 0x594 0x0 0x0 0x0 0x170b9 0x290 0x598 0x0 0x0 0x0 0x170b9 0x294 0x59c 0x0 0x0 0x0 0x170b9>;
					};

					usdhc3grp-1-200mhz {
						fsl,pins = <0x284 0x58c 0x0 0x0 0x0 0x170f9 0x280 0x588 0x0 0x0 0x0 0x100f9 0x288 0x590 0x0 0x0 0x0 0x170f9 0x28c 0x594 0x0 0x0 0x0 0x170f9 0x290 0x598 0x0 0x0 0x0 0x170f9 0x294 0x59c 0x0 0x0 0x0 0x170f9>;
					};
				};
			};

			kpp@020b8000 {
				clocks = <0x2 0x0>;
				compatible = "fsl,imx6sl-kpp", "fsl,imx21-kpp";
				interrupts = <0x0 0x52 0x4>;
				pinctrl-0 = <0xb>;
				pinctrl-names = "default";
				reg = <0x20b8000 0x4000>;
				status = "okay";
			};

			pwm@02080000 {
				#pwm-cells = <0x2>;
				clock-names = "ipg", "per";
				clocks = <0x2 0x75 0x2 0x75>;
				compatible = "fsl,imx6sl-pwm", "fsl,imx27-pwm";
				interrupts = <0x0 0x53 0x4>;
				reg = <0x2080000 0x4000>;
			};

			pwm@02084000 {
				#pwm-cells = <0x2>;
				clock-names = "ipg", "per";
				clocks = <0x2 0x76 0x2 0x76>;
				compatible = "fsl,imx6sl-pwm", "fsl,imx27-pwm";
				interrupts = <0x0 0x54 0x4>;
				reg = <0x2084000 0x4000>;
			};

			pwm@02088000 {
				#pwm-cells = <0x2>;
				clock-names = "ipg", "per";
				clocks = <0x2 0x77 0x2 0x77>;
				compatible = "fsl,imx6sl-pwm", "fsl,imx27-pwm";
				interrupts = <0x0 0x55 0x4>;
				reg = <0x2088000 0x4000>;
			};

			pwm@0208c000 {
				#pwm-cells = <0x2>;
				clock-names = "ipg", "per";
				clocks = <0x2 0x78 0x2 0x78>;
				compatible = "fsl,imx6sl-pwm", "fsl,imx27-pwm";
				interrupts = <0x0 0x56 0x4>;
				reg = <0x208c000 0x4000>;
			};

			pxp@020f0000 {
				clock-names = "pxp-axi", "disp-axi";
				clocks = <0x2 0x6f 0x2 0x0>;
				compatible = "fsl,imx6sl-pxp-dma", "fsl,imx6dl-pxp-dma";
				interrupts = <0x0 0x62 0x4>;
				reg = <0x20f0000 0x4000>;
				status = "okay";
			};

			sdma@020ec000 {
				#dma-cells = <0x3>;
				clock-names = "ipg", "ahb";
				clocks = <0x2 0x79 0x2 0x79>;
				compatible = "fsl,imx6sl-sdma", "fsl,imx35-sdma";
				fsl,sdma-ram-script-name = "imx/sdma/sdma-imx6q.bin";
				interrupts = <0x0 0x2 0x4>;
				iram = <0x12>;
				linux,phandle = <0x7>;
				phandle = <0x7>;
				reg = <0x20ec000 0x4000>;
			};

			snvs@020cc000 {
				#address-cells = <0x1>;
				#size-cells = <0x1>;
				compatible = "fsl,sec-v4.0-mon", "simple-bus";
				ranges = <0x0 0x20cc000 0x4000>;

				snvs-rtc-lp@34 {
					compatible = "fsl,sec-v4.0-mon-rtc-lp";
					interrupts = <0x0 0x13 0x4 0x0 0x14 0x4>;
					reg = <0x34 0x58>;
				};
			};

			spba-bus@02000000 {
				#address-cells = <0x1>;
				#size-cells = <0x1>;
				compatible = "fsl,spba-bus", "simple-bus";
				ranges;
				reg = <0x2000000 0x40000>;

				serial@02020000 {
					clock-names = "ipg", "per";
					clocks = <0x2 0x7e 0x2 0x7f>;
					compatible = "fsl,imx6sl-uart", "fsl,imx21-uart";
					dma-names = "rx", "tx";
					dmas = <0x7 0x19 0x4 0x0 0x7 0x1a 0x4 0x0>;
					interrupts = <0x0 0x1a 0x4>;
					pinctrl-0 = <0x8>;
					pinctrl-names = "default";
					reg = <0x2020000 0x4000>;
					status = "okay";
				};

				serial@02024000 {
					clock-names = "ipg", "per";
					clocks = <0x2 0x7e 0x2 0x7f>;
					compatible = "fsl,imx6sl-uart", "fsl,imx21-uart";
					dma-names = "rx", "tx";
					dmas = <0x7 0x1b 0x4 0x0 0x7 0x1c 0x4 0x0>;
					interrupts = <0x0 0x1b 0x4>;
					reg = <0x2024000 0x4000>;
					status = "disabled";
				};

				serial@02034000 {
					clock-names = "ipg", "per";
					clocks = <0x2 0x7e 0x2 0x7f>;
					compatible = "fsl,imx6sl-uart", "fsl,imx21-uart";
					dma-names = "rx", "tx";
					dmas = <0x7 0x1d 0x4 0x0 0x7 0x1e 0x4 0x0>;
					fsl,uart-has-rtscts;
					interrupts = <0x0 0x1c 0x4>;
					pinctrl-0 = <0x9>;
					pinctrl-names = "default";
					reg = <0x2034000 0x4000>;
					status = "okay";
				};

				serial@02038000 {
					clock-names = "ipg", "per";
					clocks = <0x2 0x7e 0x2 0x7f>;
					compatible = "fsl,imx6sl-uart", "fsl,imx21-uart";
					dma-names = "rx", "tx";
					dmas = <0x7 0x1f 0x4 0x0 0x7 0x20 0x4 0x0>;
					interrupts = <0x0 0x1d 0x4>;
					pinctrl-0 = <0xa>;
					pinctrl-names = "default";
					reg = <0x2038000 0x4000>;
					status = "okay";
				};

				spdif@02004000 {
					clock-names = "core", "rxtx0", "rxtx1", "rxtx2", "rxtx3", "rxtx4", "rxtx5", "rxtx6", "rxtx7", "dma";
					clocks = <0x2 0x7a 0x2 0x2 0x2 0x7a 0x2 0x0 0x2 0x0 0x2 0x0 0x2 0x3f 0x2 0x0 0x2 0x0 0x2 0x88>;
					compatible = "fsl,imx6sl-spdif", "fsl,imx35-spdif";
					dma-names = "rx", "tx";
					dmas = <0x7 0xe 0x12 0x0 0x7 0xf 0x12 0x0>;
					interrupts = <0x0 0x34 0x4>;
					reg = <0x2004000 0x4000>;
					status = "disabled";
				};

				ssi@02028000 {
					clock-names = "ipg", "baud";
					clocks = <0x2 0x7b 0x2 0x7b>;
					compatible = "fsl,imx6sl-ssi", "fsl,imx21-ssi";
					dma-names = "rx", "tx";
					dmas = <0x7 0x25 0x1 0x0 0x7 0x26 0x1 0x0>;
					interrupts = <0x0 0x2e 0x4>;
					reg = <0x2028000 0x4000>;
					status = "disabled";
				};

				ssi@0202c000 {
					clock-names = "ipg", "baud";
					clocks = <0x2 0x7c 0x2 0x7c>;
					compatible = "fsl,imx6sl-ssi", "fsl,imx21-ssi";
					dma-names = "rx", "tx";
					dmas = <0x7 0x29 0x1 0x0 0x7 0x2a 0x1 0x0>;
					interrupts = <0x0 0x2f 0x4>;
					reg = <0x202c000 0x4000>;
					status = "disabled";
				};

				ssi@02030000 {
					clock-names = "ipg", "baud";
					clocks = <0x2 0x7d 0x2 0x7d>;
					compatible = "fsl,imx6sl-ssi", "fsl,imx21-ssi";
					dma-names = "rx", "tx";
					dmas = <0x7 0x2d 0x1 0x0 0x7 0x2e 0x1 0x0>;
					interrupts = <0x0 0x30 0x4>;
					reg = <0x2030000 0x4000>;
					status = "disabled";
				};
			};

			spdc@020e8000 {
				interrupts = <0x0 0x6 0x4>;
				reg = <0x20e8000 0x4000>;
			};

			sram@00900000 {
				clock-names = "ocram";
				clocks = <0x2 0x74>;
				compatible = "fsl,lpm-sram";
				reg = <0x900000 0x4000>;
			};

			sram@00904000 {
				clock-names = "ocram";
				clocks = <0x2 0x74>;
				compatible = "fsl,ddr-lpm-sram";
				reg = <0x904000 0x1000>;
			};

			sram@00905000 {
				clock-names = "ocram";
				clocks = <0x2 0x74>;
				compatible = "mmio-sram";
				linux,phandle = <0x12>;
				phandle = <0x12>;
				reg = <0x905000 0x1b000>;
			};

			src@020d8000 {
				#reset-cells = <0x1>;
				compatible = "fsl,imx6sl-src", "fsl,imx51-src";
				interrupts = <0x0 0x5b 0x4 0x0 0x60 0x4>;
				reg = <0x20d8000 0x4000>;
			};

			tempmon {
				clocks = <0x2 0x5>;
				compatible = "fsl,imx6sl-tempmon", "fsl,imx6q-tempmon";
				fsl,tempmon = <0xc>;
				fsl,tempmon-data = <0xd>;
				interrupts = <0x0 0x31 0x4>;
			};

			usbphy@020c9000 {
				clocks = <0x2 0xa>;
				compatible = "fsl,imx6sl-usbphy", "fsl,imx23-usbphy";
				fsl,anatop = <0xc>;
				interrupts = <0x0 0x2c 0x4>;
				linux,phandle = <0x14>;
				phandle = <0x14>;
				phy-3p0-supply = <0xe>;
				reg = <0x20c9000 0x1000>;
			};

			usbphy@020ca000 {
				clocks = <0x2 0xb>;
				compatible = "fsl,imx6sl-usbphy", "fsl,imx23-usbphy";
				fsl,anatop = <0xc>;
				interrupts = <0x0 0x2d 0x4>;
				linux,phandle = <0x18>;
				phandle = <0x18>;
				phy-3p0-supply = <0xe>;
				reg = <0x20ca000 0x1000>;
			};

			usbphy_nop1 {
				clock-names = "main_clk";
				clocks = <0x2 0xa>;
				compatible = "usb-nop-xceiv";
				linux,phandle = <0x19>;
				phandle = <0x19>;
			};

			wdog@020bc000 {
				clocks = <0x2 0x0>;
				compatible = "fsl,imx6sl-wdt", "fsl,imx21-wdt";
				interrupts = <0x0 0x50 0x4>;
				reg = <0x20bc000 0x4000>;
			};

			wdog@020c0000 {
				clocks = <0x2 0x0>;
				compatible = "fsl,imx6sl-wdt", "fsl,imx21-wdt";
				interrupts = <0x0 0x51 0x4>;
				reg = <0x20c0000 0x4000>;
				status = "disabled";
			};
		};

		aips-bus@02100000 {
			#address-cells = <0x1>;
			#size-cells = <0x1>;
			compatible = "fsl,aips-bus", "simple-bus";
			ranges;
			reg = <0x2100000 0x100000>;

			audmux@021d8000 {
				compatible = "fsl,imx6sl-audmux", "fsl,imx31-audmux";
				reg = <0x21d8000 0x4000>;
				status = "disabled";
			};

			i2c@021a0000 {
				#address-cells = <0x1>;
				#size-cells = <0x0>;
				clock-frequency = <0x5b8d8>;
				clocks = <0x2 0x6a>;
				compatible = "fsl,imx6sl-i2c", "fsl,imx21-i2c";
				interrupts = <0x0 0x24 0x4>;
				pinctrl-0 = <0x21>;
				pinctrl-names = "default";
				reg = <0x21a0000 0x4000>;
				status = "okay";

				bd7181x@4b {
					compatible = "rohm,bd71815";
					gpio_intr = <0x22 0x14 0x1>;
					reg = <0x4b>;

					gpo {
						rohm,mode = <0x3>;
					};

					regulators {
						#address-cells = <0x1>;
						#size-cells = <0x0>;

						regulator@0 {
							linux,phandle = <0x5>;
							phandle = <0x5>;
							reg = <0x0>;
							regulator-always-on;
							regulator-boot-on;
							regulator-compatible = "buck1";
							regulator-max-microvolt = <0x1e8480>;
							regulator-min-microvolt = <0xc3500>;
							regulator-ramp-delay = <0x186a>;
						};

						regulator@1 {
							linux,phandle = <0x3>;
							phandle = <0x3>;
							reg = <0x1>;
							regulator-always-on;
							regulator-boot-on;
							regulator-compatible = "buck2";
							regulator-max-microvolt = <0x1e8480>;
							regulator-min-microvolt = <0xc3500>;
							regulator-ramp-delay = <0x186a>;
						};

						regulator@10 {
							reg = <0xa>;
							regulator-always-on;
							regulator-compatible = "dvref";
						};

						regulator@11 {
							reg = <0xb>;
							regulator-compatible = "lpsr";
						};

						regulator@12 {
							reg = <0xc>;
							regulator-compatible = "wled";
							regulator-max-microamp = <0x61a8>;
							regulator-min-microamp = <0xa>;
						};

						regulator@2 {
							reg = <0x2>;
							regulator-always-on;
							regulator-boot-on;
							regulator-compatible = "buck3";
							regulator-max-microvolt = <0x2932e0>;
							regulator-min-microvolt = <0x124f80>;
						};

						regulator@3 {
							reg = <0x3>;
							regulator-always-on;
							regulator-compatible = "buck4";
							regulator-max-microvolt = <0x1c3a90>;
							regulator-min-microvolt = <0x10c8e0>;
						};

						regulator@4 {
							reg = <0x4>;
							regulator-always-on;
							regulator-compatible = "buck5";
							regulator-max-microvolt = <0x325aa0>;
							regulator-min-microvolt = <0x1b7740>;
						};

						regulator@5 {
							reg = <0x5>;
							regulator-always-on;
							regulator-compatible = "ldo1";
							regulator-max-microvolt = <0x325aa0>;
							regulator-min-microvolt = <0xc3500>;
						};

						regulator@6 {
							reg = <0x6>;
							regulator-always-on;
							regulator-compatible = "ldo2";
							regulator-max-microvolt = <0x325aa0>;
							regulator-min-microvolt = <0xc3500>;
						};

						regulator@7 {
							linux,phandle = <0x16>;
							phandle = <0x16>;
							reg = <0x7>;
							regulator-always-on;
							regulator-compatible = "ldo3";
							regulator-max-microvolt = <0x2dc6c0>;
							regulator-min-microvolt = <0x2dc6c0>;
							regulator-name = "ldo3";
						};

						regulator@8 {
							reg = <0x8>;
							regulator-compatible = "ldo4";
							regulator-max-microvolt = <0x325aa0>;
							regulator-min-microvolt = <0xc3500>;
						};

						regulator@9 {
							reg = <0x9>;
							regulator-compatible = "ldo5";
							regulator-max-microvolt = <0x325aa0>;
							regulator-min-microvolt = <0xc3500>;
							regulator-name = "ldo5";
						};
					};
				};

				fp9928@48 {
					compatible = "fp9928";
					reg = <0x48>;
				};
			};

			i2c@021a4000 {
				#address-cells = <0x1>;
				#size-cells = <0x0>;
				clock-frequency = <0x5b8d8>;
				clocks = <0x2 0x6b>;
				compatible = "fsl,imx6sl-i2c", "fsl,imx21-i2c";
				interrupts = <0x0 0x25 0x4>;
				pinctrl-0 = <0x23>;
				pinctrl-names = "default";
				reg = <0x21a4000 0x4000>;
				status = "okay";

				zforce2@50 {
					compatible = "zforce2";
					reg = <0x50>;
				};
			};

			i2c@021a8000 {
				#address-cells = <0x1>;
				#size-cells = <0x0>;
				clock-frequency = <0x5b8d8>;
				clocks = <0x2 0x6c>;
				compatible = "fsl,imx6sl-i2c", "fsl,imx21-i2c";
				interrupts = <0x0 0x26 0x4>;
				pinctrl-0 = <0x24>;
				pinctrl-names = "default";
				reg = <0x21a8000 0x4000>;
				status = "okay";
			};

			mmdc@021b0000 {
				compatible = "fsl,imx6sl-mmdc", "fsl,imx6q-mmdc";
				reg = <0x21b0000 0x4000>;
			};

			ocotp-ctrl@021bc000 {
				clocks = <0x2 0x6d>;
				compatible = "syscon";
				linux,phandle = <0xd>;
				phandle = <0xd>;
				reg = <0x21bc000 0x4000>;
			};

			ocotp-fuse@021bc000 {
				clocks = <0x2 0x6d>;
				compatible = "fsl,imx6sl-ocotp", "fsl,imx6q-ocotp";
				reg = <0x21bc000 0x4000>;
			};

			rng@021b4000 {
				clocks = <0x2 0x0>;
				compatible = "fsl,imx6sl-rng", "fsl,imx-rng", "imx-rng";
				interrupts = <0x0 0x5 0x4>;
				reg = <0x21b4000 0x4000>;
			};

			usb@02184000 {
				clocks = <0x2 0x80>;
				compatible = "fsl,imx6sl-usb", "fsl,imx27-usb";
				disable-over-current;
				fsl,anatop = <0xc>;
				fsl,usbmisc = <0x15 0x0>;
				fsl,usbphy = <0x14>;
				imx6-usb-charger-detection;
				interrupts = <0x0 0x2b 0x4>;
				pinctrl-0 = <0x17>;
				pinctrl-names = "default";
				reg = <0x2184000 0x200>;
				status = "okay";
				vbus-supply = <0x16>;
			};

			usb@02184200 {
				clocks = <0x2 0x80>;
				compatible = "fsl,imx6sl-usb", "fsl,imx27-usb";
				fsl,usbmisc = <0x15 0x1>;
				fsl,usbphy = <0x18>;
				interrupts = <0x0 0x2a 0x4>;
				reg = <0x2184200 0x200>;
				status = "disabled";
			};

			usb@02184400 {
				clocks = <0x2 0x80>;
				compatible = "fsl,imx6sl-usb", "fsl,imx27-usb";
				fsl,anatop = <0xc>;
				fsl,usbmisc = <0x15 0x2>;
				fsl,usbphy = <0x19>;
				interrupts = <0x0 0x28 0x4>;
				phy_type = "hsic";
				reg = <0x2184400 0x200>;
				status = "disabled";
			};

			usbmisc@02184800 {
				#index-cells = <0x1>;
				clocks = <0x2 0x80>;
				compatible = "fsl,imx6sl-usbmisc", "fsl,imx6q-usbmisc";
				linux,phandle = <0x15>;
				phandle = <0x15>;
				reg = <0x2184800 0x200>;
				vbus-wakeup-supply = <0x1a>;
			};

			usdhc@02190000 {
				bus-width = <0x4>;
				clock-names = "ipg", "ahb", "per";
				clocks = <0x2 0x81 0x2 0x81 0x2 0x81>;
				compatible = "fsl,imx6sl-usdhc", "fsl,imx6q-usdhc";
				fsl,delay-line;
				interrupts = <0x0 0x16 0x4>;
				keep-power-in-suspend;
				non-removable;
				pinctrl-0 = <0x1b>;
				pinctrl-1 = <0x1c>;
				pinctrl-2 = <0x1d>;
				pinctrl-names = "default", "state_100mhz", "state_200mhz";
				reg = <0x2190000 0x4000>;
				status = "okay";
			};

			usdhc@02194000 {
				bus-width = <0x8>;
				clock-names = "ipg", "ahb", "per";
				clocks = <0x2 0x82 0x2 0x82 0x2 0x82>;
				compatible = "fsl,imx6sl-usdhc", "fsl,imx6q-usdhc";
				fsl,ddr50-support-override;
				fsl,delay-line;
				fsl,sdr104-support-override;
				fsl,sdr50-support-override;
				fsl,sig-voltage-switch-disable;
				interrupts = <0x0 0x17 0x4>;
				keep-power-in-suspend;
				non-removable;
				pinctrl-0 = <0x1e>;
				pinctrl-1 = <0x1f>;
				pinctrl-2 = <0x20>;
				pinctrl-names = "default", "state_100mhz", "state_200mhz";
				reg = <0x2194000 0x4000>;
				status = "okay";
			};

			usdhc@02198000 {
				bus-width = <0x4>;
				clock-names = "ipg", "ahb", "per";
				clocks = <0x2 0x83 0x2 0x83 0x2 0x83>;
				compatible = "fsl,imx6sl-usdhc", "fsl,imx6q-usdhc";
				interrupts = <0x0 0x18 0x4>;
				reg = <0x2198000 0x4000>;
				status = "disabled";
			};

			usdhc@0219c000 {
				bus-width = <0x4>;
				clock-names = "ipg", "ahb", "per";
				clocks = <0x2 0x84 0x2 0x84 0x2 0x84>;
				compatible = "fsl,imx6sl-usdhc", "fsl,imx6q-usdhc";
				interrupts = <0x0 0x19 0x4>;
				reg = <0x219c000 0x4000>;
				status = "disabled";
			};

			weim@021b8000 {
				interrupts = <0x0 0xe 0x4>;
				reg = <0x21b8000 0x4000>;
			};
		};

		busfreq {
			clock-names = "pll2_bus", "pll2_pfd2_396m", "pll2_198m", "arm", "pll3_usb_otg", "periph", "periph_pre", "periph_clk2", "periph_clk2_sel", "osc", "pll1_sys", "periph2", "ahb", "ocram", "pll1_sw", "periph2_pre", "periph2_clk2_sel", "periph2_clk2", "step";
			clocks = <0x2 0x4 0x2 0x14 0x2 0x19 0x2 0x5f 0x2 0x5 0x2 0x3a 0x2 0x22 0x2 0x3d 0x2 0x24 0x2 0x2 0x2 0x3 0x2 0x3b 0x2 0x5d 0x2 0x74 0x2 0x1e 0x2 0x21 0x2 0x23 0x2 0x3e 0x2 0x1d>;
			compatible = "fsl,imx6_busfreq";
			fsl,max_ddr_freq = <0x17d78400>;
		};

		l2-cache@00a02000 {
			arm,data-latency = <0x4 0x2 0x3>;
			arm,tag-latency = <0x4 0x2 0x3>;
			cache-level = <0x2>;
			cache-unified;
			compatible = "arm,pl310-cache";
			interrupts = <0x0 0x5c 0x4>;
			linux,phandle = <0x1>;
			phandle = <0x1>;
			reg = <0xa02000 0x1000>;
		};

		pmu {
			compatible = "arm,cortex-a9-pmu";
			interrupts = <0x0 0x5e 0x4>;
		};

		ramoops_device {
			compatible = "fsl,mxc_ramoops";
			console_size = <0x40000>;
			dump_oops = <0x1>;
			ftrace_size = <0x40000>;
			record_size = <0x80000>;
			status = "okay";
		};
	};

	usb_vbus_wakeup {
		compatible = "fsl,imx6-dummy-ldo2p5";
		linux,phandle = <0x1a>;
		phandle = <0x1a>;
	};

	wifi_brcm {
		compatible = "bcm,bcm43430";
		wl_host_wake = <0x26 0x1f 0x0>;
		wl_reg_on = <0x25 0xf 0x0>;
	};
};
